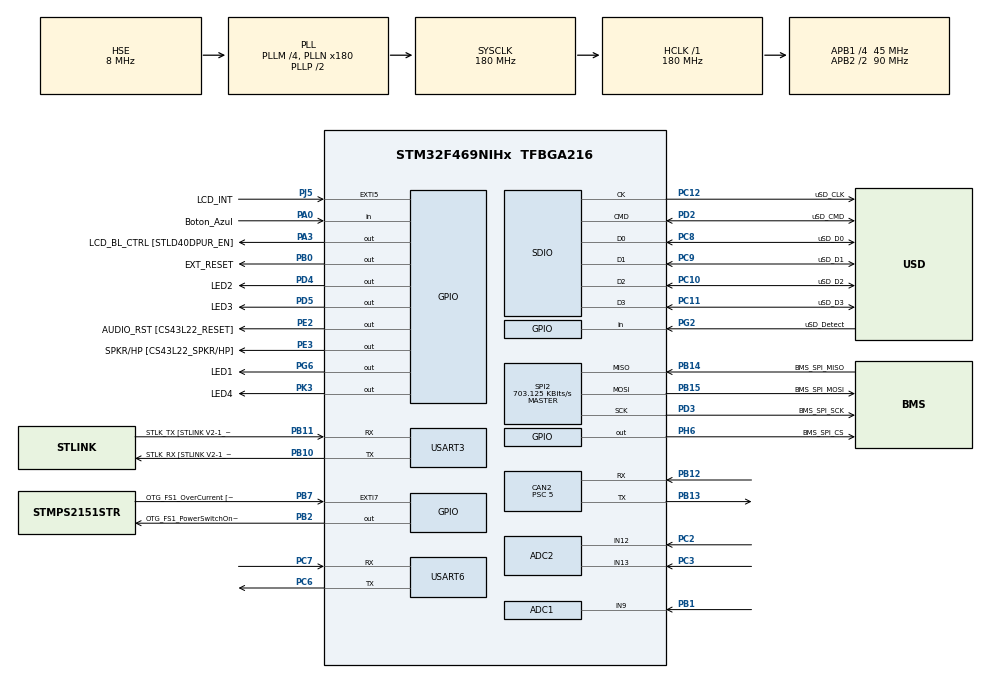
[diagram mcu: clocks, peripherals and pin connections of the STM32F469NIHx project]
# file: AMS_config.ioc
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ADC1.Channel-1\#ChannelRegularConversion=ADC_CHANNEL_9
ADC1.Channel-2\#ChannelRegularConversion=ADC_CHANNEL_TEMPSENSOR
ADC1.Channel-3\#ChannelRegularConversion=ADC_CHANNEL_VREFINT
ADC1.ClockPrescaler=ADC_CLOCK_SYNC_PCLK_DIV4
ADC1.DMAContinuousRequests=ENABLE
ADC1.ExternalTrigConv=ADC_EXTERNALTRIGCONV_T2_TRGO
ADC1.NbrOfConversion=3
ADC1.NbrOfConversionFlag=1
ADC1.Rank-1\#ChannelRegularConversion=1
ADC1.Rank-2\#ChannelRegularConversion=2
ADC1.Rank-3\#ChannelRegularConversion=3
ADC1.SamplingTime-1\#ChannelRegularConversion=ADC_SAMPLETIME_15CYCLES
ADC1.SamplingTime-2\#ChannelRegularConversion=ADC_SAMPLETIME_480CYCLES
ADC1.SamplingTime-3\#ChannelRegularConversion=ADC_SAMPLETIME_480CYCLES
ADC1.master=1
ADC2.Channel-0\#ChannelRegularConversion=ADC_CHANNEL_12
ADC2.Channel-1\#ChannelRegularConversion=ADC_CHANNEL_13
ADC2.ClockPrescaler=ADC_CLOCK_SYNC_PCLK_DIV4
ADC2.ContinuousConvMode=DISABLE
ADC2.DMAContinuousRequests=ENABLE
ADC2.ExternalTrigConv=ADC_EXTERNALTRIGCONV_T3_TRGO
ADC2.NbrOfConversion=2
ADC2.NbrOfConversionFlag=1
ADC2.Rank-0\#ChannelRegularConversion=1
ADC2.Rank-1\#ChannelRegularConversion=2
ADC2.SamplingTime-0\#ChannelRegularConversion=ADC_SAMPLETIME_15CYCLES
ADC2.SamplingTime-1\#ChannelRegularConversion=ADC_SAMPLETIME_15CYCLES
CAN2.BS1=CAN_BS1_15TQ
CAN2.BS2=CAN_BS2_2TQ
CAN2.CalculateBaudRate=500000
CAN2.CalculateTimeBit=2000
CAN2.CalculateTimeQuantum=111.11111111111111
CAN2.Prescaler=5
DSIHOST_CKN.GPIO_Label=DSI_CK_N
DSIHOST_CKN.Signal=DSIHOST_CKN
DSIHOST_CKP.GPIO_Label=DSI_CK_P
DSIHOST_CKP.Signal=DSIHOST_CKP
DSIHOST_D0N.GPIO_Label=DSI_D0_N
DSIHOST_D0N.Signal=DSIHOST_D0N
DSIHOST_D0P.GPIO_Label=DSI_D0_P
DSIHOST_D0P.Signal=DSIHOST_D0P
DSIHOST_D1N.GPIO_Label=DSI_D1_N
DSIHOST_D1N.Signal=DSIHOST_D1N
DSIHOST_D1P.GPIO_Label=DSI_D1_P
DSIHOST_D1P.Signal=DSIHOST_D1P
Dma.ADC1.1.Direction=DMA_PERIPH_TO_MEMORY
Dma.ADC1.1.FIFOMode=DMA_FIFOMODE_DISABLE
Dma.ADC1.1.Instance=DMA2_Stream0
Dma.ADC1.1.MemDataAlignment=DMA_MDATAALIGN_HALFWORD
Dma.ADC1.1.MemInc=DMA_MINC_ENABLE
Dma.ADC1.1.Mode=DMA_CIRCULAR
Dma.ADC1.1.PeriphDataAlignment=DMA_PDATAALIGN_HALFWORD
Dma.ADC1.1.PeriphInc=DMA_PINC_DISABLE
Dma.ADC1.1.Priority=DMA_PRIORITY_LOW
Dma.ADC2.0.Direction=DMA_PERIPH_TO_MEMORY
Dma.ADC2.0.FIFOMode=DMA_FIFOMODE_DISABLE
Dma.ADC2.0.Instance=DMA2_Stream2
Dma.ADC2.0.MemDataAlignment=DMA_MDATAALIGN_HALFWORD
Dma.ADC2.0.MemInc=DMA_MINC_ENABLE
Dma.ADC2.0.Mode=DMA_CIRCULAR
Dma.ADC2.0.PeriphDataAlignment=DMA_PDATAALIGN_HALFWORD
Dma.ADC2.0.PeriphInc=DMA_PINC_DISABLE
Dma.ADC2.0.Priority=DMA_PRIORITY_LOW
Dma.Request0=ADC2
Dma.Request1=ADC1
Dma.Request2=USART6_RX
Dma.USART6_RX.2.Direction=DMA_PERIPH_TO_MEMORY
Dma.USART6_RX.2.FIFOMode=DMA_FIFOMODE_DISABLE
Dma.USART6_RX.2.Instance=DMA2_Stream1
Dma.USART6_RX.2.MemDataAlignment=DMA_MDATAALIGN_BYTE
Dma.USART6_RX.2.MemInc=DMA_MINC_ENABLE
Dma.USART6_RX.2.Mode=DMA_CIRCULAR
Dma.USART6_RX.2.PeriphDataAlignment=DMA_PDATAALIGN_BYTE
Dma.USART6_RX.2.PeriphInc=DMA_PINC_DISABLE
Dma.USART6_RX.2.Priority=DMA_PRIORITY_LOW
FATFS.BSP.number=1
FATFS._USE_LFN=3
FATFS0.BSP.STBoard=false
FATFS0.BSP.api=Unknown
FATFS0.BSP.instance=PG2
FATFS0.BSP.ip=GPIO
FATFS0.BSP.mode=Input
FATFS0.BSP.name=Detect_SDIO
FATFS0.BSP.solution=PG2
FREERTOS.Tasks01=defaultTask,24,256,StartDefaultTask,Default,NULL,Dynamic,NULL,NULL;Task_ADC,24,256,ADC_Start,Default,NULL,Dynamic,NULL,NULL;Task_SD_Card,24,512,SD_Card_Start,Default,NULL,Dynamic,NULL,NULL;Task_CAN,24,256,CAN_Start,Default,NULL,Dynamic,NULL,NULL;Task_Flash_Memo,8,256,Flash_Memory_Start,Default,NULL,Dynamic,NULL,NULL;GPS_Task,24,256,GPS_Start_Task,Default,NULL,Dynamic,NULL,NULL
Mcu.Family=STM32F4
Mcu.Name=STM32F469NIHx
Mcu.Package=TFBGA216
NVIC.CAN2_RX0_IRQn=true\:5\:0\:false\:false\:true\:true\:true\:true\:true
NVIC.DMA2_Stream0_IRQn=true\:5\:0\:false\:false\:true\:true\:false\:true\:true
NVIC.DMA2_Stream1_IRQn=true\:5\:0\:false\:false\:true\:true\:false\:true\:true
NVIC.DMA2_Stream2_IRQn=true\:5\:0\:false\:false\:true\:true\:false\:true\:true
NVIC.PriorityGroup=NVIC_PRIORITYGROUP_4
NVIC.SDIO_IRQn=true\:5\:0\:false\:false\:true\:true\:true\:true\:true
NVIC.USART6_IRQn=true\:5\:0\:false\:false\:true\:true\:true\:true\:true
PA0/WKUP.GPIO_Label=Boton_Azul
PA0/WKUP.Signal=GPIO_Input
PA10.GPIO_Label=USB_FS1_ID
PA10.GPIO_Mode=GPIO_MODE_AF_PP
PA10.GPIO_PuPd=GPIO_NOPULL
PA10.GPIO_Speed=GPIO_SPEED_FREQ_VERY_HIGH
PA10.Signal=USB_OTG_FS_ID
PA11.GPIO_Label=USB_FS1_N
PA11.GPIO_Mode=GPIO_MODE_AF_PP
PA11.GPIO_PuPd=GPIO_NOPULL
PA11.GPIO_Speed=GPIO_SPEED_FREQ_VERY_HIGH
PA11.Signal=USB_OTG_FS_DM
PA12.GPIO_Label=USB_FS1_P
PA12.GPIO_Mode=GPIO_MODE_AF_PP
PA12.GPIO_PuPd=GPIO_NOPULL
PA12.GPIO_Speed=GPIO_SPEED_FREQ_VERY_HIGH
PA12.Signal=USB_OTG_FS_DP
PA13.GPIO_Label=SWDIO
PA13.Signal=SYS_JTMS-SWDIO
PA14.GPIO_Label=SWCLK
PA14.Signal=SYS_JTCK-SWCLK
PA3.GPIO_Label=LCD_BL_CTRL [STLD40DPUR_EN]
PA3.Signal=GPIO_Output
PA5.Signal=ADCx_IN5
PA9.GPIO_Label=VBUS_FS1
PA9.GPIO_Mode=GPIO_MODE_AF_PP
PA9.GPIO_PuPd=GPIO_NOPULL
PA9.GPIO_Speed=GPIO_SPEED_FREQ_VERY_HIGH
PA9.Signal=USB_OTG_FS_VBUS
PB0.GPIO_Label=EXT_RESET
PB0.Signal=GPIO_Output
PB1.Signal=ADCx_IN9
PB10.GPIO_Label=STLK_RX [STLINK V2-1_U2_RX]
PB10.Mode=Asynchronous
PB10.Signal=USART3_TX
PB11.GPIO_Label=STLK_TX [STLINK V2-1_U2_TX]
PB11.Mode=Asynchronous
PB11.Signal=USART3_RX
PB12.Mode=CAN_Activate
PB12.Signal=CAN2_RX
PB13.Mode=CAN_Activate
PB13.Signal=CAN2_TX
PB14.GPIO_Label=BMS_SPI_MISO
PB14.Mode=Full_Duplex_Master
PB14.Signal=SPI2_MISO
PB15.GPIO_Label=BMS_SPI_MOSI
PB15.Mode=Full_Duplex_Master
PB15.Signal=SPI2_MOSI
PB2/BOOT1.GPIO_Label=OTG_FS1_PowerSwitchOn [STMPS2151STR_En]
PB2/BOOT1.Signal=GPIO_Output
PB3.GPIO_Label=I2S3_CK
PB3.GPIO_Mode=GPIO_MODE_AF_PP
PB3.GPIO_PuPd=GPIO_NOPULL
PB3.GPIO_Speed=GPIO_SPEED_FREQ_LOW
PB3.Signal=I2S3_CK
PB6.GPIO_Label=QSPI_BK1_NCS [N25Q128A13EF840F_S]
PB6.GPIO_Mode=GPIO_MODE_AF_PP
PB6.GPIO_PuPd=GPIO_NOPULL
PB6.GPIO_Speed=GPIO_SPEED_FREQ_VERY_HIGH
PB6.Signal=QUADSPI_BK1_NCS
PB7.GPIO_Label=OTG_FS1_OverCurrent [STMPS2151STR_FAULT]
PB7.GPIO_ModeDefaultEXTI=GPIO_MODE_IT_RISING
PB7.GPIO_PuPd=GPIO_NOPULL
PB7.Signal=GPXTI7
PB8.GPIO_Label=I2C1_SCL
PB8.GPIO_Mode=GPIO_MODE_AF_OD
PB8.GPIO_PuPdOD=GPIO_PULLUP
PB8.GPIO_Speed=GPIO_SPEED_FREQ_VERY_HIGH
PB8.Signal=I2C1_SCL
PB9.GPIO_Label=I2C1_SDA
PB9.GPIO_Mode=GPIO_MODE_AF_OD
PB9.GPIO_PuPdOD=GPIO_PULLUP
PB9.GPIO_Speed=GPIO_SPEED_FREQ_VERY_HIGH
PB9.Signal=I2C1_SDA
PC0.GPIO_Label=SDNWE [MT48LC4M32B2B5-6A_WE]
PC0.Signal=FMC_SDNWE
PC10.GPIO_Label=uSD_D2
PC10.GPIO_Mode=GPIO_MODE_AF_PP
PC10.GPIO_PuPd=GPIO_NOPULL
PC10.GPIO_Speed_High_Default=GPIO_SPEED_FREQ_VERY_HIGH
PC10.Mode=SD_4_bits_Wide_bus
PC10.Signal=SDIO_D2
PC11.GPIO_Label=uSD_D3
PC11.GPIO_Mode=GPIO_MODE_AF_PP
PC11.GPIO_PuPd=GPIO_NOPULL
PC11.GPIO_Speed_High_Default=GPIO_SPEED_FREQ_VERY_HIGH
PC11.Mode=SD_4_bits_Wide_bus
PC11.Signal=SDIO_D3
PC12.GPIO_Label=uSD_CLK
PC12.GPIO_Mode=GPIO_MODE_AF_PP
PC12.GPIO_PuPd=GPIO_NOPULL
PC12.GPIO_Speed_High_Default=GPIO_SPEED_FREQ_VERY_HIGH
PC12.Mode=SD_4_bits_Wide_bus
PC12.Signal=SDIO_CK
PC14/OSC32_IN.Mode=LSE-External-Oscillator
PC14/OSC32_IN.Signal=RCC_OSC32_IN
PC15/OSC32_OUT.Mode=LSE-External-Oscillator
PC15/OSC32_OUT.Signal=RCC_OSC32_OUT
PC2.Signal=ADCx_IN12
PC3.Signal=ADCx_IN13
PC6.Mode=Asynchronous
PC6.Signal=USART6_TX
PC7.Mode=Asynchronous
PC7.Signal=USART6_RX
PC8.GPIO_Label=uSD_D0
PC8.GPIO_Mode=GPIO_MODE_AF_PP
PC8.GPIO_PuPd=GPIO_NOPULL
PC8.GPIO_Speed_High_Default=GPIO_SPEED_FREQ_VERY_HIGH
PC8.Mode=SD_4_bits_Wide_bus
PC8.Signal=SDIO_D0
PC9.GPIO_Label=uSD_D1
PC9.GPIO_Mode=GPIO_MODE_AF_PP
PC9.GPIO_PuPd=GPIO_NOPULL
PC9.GPIO_Speed_High_Default=GPIO_SPEED_FREQ_VERY_HIGH
PC9.Mode=SD_4_bits_Wide_bus
PC9.Signal=SDIO_D1
PD0.GPIO_Label=D2
PD0.GPIO_Mode=GPIO_MODE_AF_PP
PD0.GPIO_PuPd=GPIO_NOPULL
PD0.GPIO_Speed_High_Default=GPIO_SPEED_FREQ_VERY_HIGH
PD0.Signal=FMC_D2_DA2
PD1.GPIO_Label=D3
PD1.GPIO_Mode=GPIO_MODE_AF_PP
PD1.GPIO_PuPd=GPIO_NOPULL
PD1.GPIO_Speed_High_Default=GPIO_SPEED_FREQ_VERY_HIGH
PD1.Signal=FMC_D3_DA3
PD3.GPIO_Label=BMS_SPI_SCK
PD3.Mode=Full_Duplex_Master
PD3.Signal=SPI2_SCK
PD10.GPIO_Label=D15
PD10.Signal=FMC_D15_DA15
PD13.GPIO_Label=MIC_CK [MP34DT01TR_CLK]
PD13.Signal=S_TIM4_CH2
PD14.GPIO_Label=D0
PD14.Signal=FMC_D0_DA0
PD15.GPIO_Label=D1
PD15.Signal=FMC_D1_DA1
PD2.GPIO_Label=uSD_CMD
PD2.GPIO_Mode=GPIO_MODE_AF_PP
PD2.GPIO_PuPd=GPIO_NOPULL
PD2.GPIO_Speed_High_Default=GPIO_SPEED_FREQ_VERY_HIGH
PD2.Mode=SD_4_bits_Wide_bus
PD2.Signal=SDIO_CMD
PD4.GPIO_Label=LED2
PD4.GPIO_ModeDefaultOutputPP=GPIO_MODE_OUTPUT_PP
PD4.GPIO_PuPd=GPIO_NOPULL
PD4.GPIO_Speed=GPIO_SPEED_FREQ_LOW
PD4.Signal=GPIO_Output
PD5.GPIO_Label=LED3
PD5.GPIO_ModeDefaultOutputPP=GPIO_MODE_OUTPUT_PP
PD5.GPIO_PuPd=GPIO_NOPULL
PD5.GPIO_Speed=GPIO_SPEED_FREQ_LOW
PD5.Signal=GPIO_Output
PD6.GPIO_Label=MIC_DATA [MP34DT01TR_DOUT]
PD6.GPIO_Mode=GPIO_MODE_AF_PP
PD6.GPIO_PuPd=GPIO_NOPULL
PD6.GPIO_Speed=GPIO_SPEED_FREQ_LOW
PD6.Signal=SAI1_SD_A
PD8.GPIO_Label=D13
PD8.Signal=FMC_D13_DA13
PD9.GPIO_Label=D14
PD9.Signal=FMC_D14_DA14
PE0.GPIO_Label=FMC_NBL0 [ MT48LC4M32B2B5-6A_DQM0]
PE0.GPIO_Mode=GPIO_MODE_AF_PP
PE0.GPIO_PuPd=GPIO_NOPULL
PE0.GPIO_Speed_High_Default=GPIO_SPEED_FREQ_VERY_HIGH
PE0.Signal=FMC_NBL0
PE1.GPIO_Label=FMC_NBL1 [ MT48LC4M32B2B5-6A_DQM1]
PE1.GPIO_Mode=GPIO_MODE_AF_PP
PE1.GPIO_PuPd=GPIO_NOPULL
PE1.GPIO_Speed_High_Default=GPIO_SPEED_FREQ_VERY_HIGH
PE1.Signal=FMC_NBL1
PE10.GPIO_Label=D7
PE10.Signal=FMC_D7_DA7
PE11.GPIO_Label=D8
PE11.Signal=FMC_D8_DA8
PE12.GPIO_Label=D9
PE12.Signal=FMC_D9_DA9
PE13.GPIO_Label=D10
PE13.Signal=FMC_D10_DA10
PE14.GPIO_Label=D11
PE14.Signal=FMC_D11_DA11
PE15.GPIO_Label=D12
PE15.Signal=FMC_D12_DA12
PE2.GPIO_Label=AUDIO_RST [CS43L22_RESET]
PE2.GPIO_ModeDefaultOutputPP=GPIO_MODE_OUTPUT_PP
PE2.GPIO_PuPd=GPIO_NOPULL
PE2.GPIO_Speed=GPIO_SPEED_FREQ_LOW
PE2.Signal=GPIO_Output
PE3.GPIO_Label=SPKR/HP [CS43L22_SPKR/HP]
PE3.GPIO_ModeDefaultOutputPP=GPIO_MODE_OUTPUT_PP
PE3.GPIO_PuPd=GPIO_NOPULL
PE3.GPIO_Speed=GPIO_SPEED_FREQ_LOW
PE3.Signal=GPIO_Output
PE4.GPIO_Label=SAI1_FSA [CS43L22_LRCK]
PE4.GPIO_Mode=GPIO_MODE_AF_PP
PE4.GPIO_PuPd=GPIO_NOPULL
PE4.GPIO_Speed=GPIO_SPEED_FREQ_LOW
PE4.Signal=SAI1_FS_A
PE5.GPIO_Label=SAI1_SCKA [CS43L22_CLK]
PE5.GPIO_Mode=GPIO_MODE_AF_PP
PE5.GPIO_PuPd=GPIO_NOPULL
PE5.GPIO_Speed=GPIO_SPEED_FREQ_LOW
PE5.Signal=SAI1_SCK_A
PE7.GPIO_Label=D4
PE7.Signal=FMC_D4_DA4
PE8.GPIO_Label=D5
PE8.Signal=FMC_D5_DA5
PE9.GPIO_Label=D6
PE9.Signal=FMC_D6_DA6
PF0.GPIO_Label=A0
PF0.GPIO_Mode=GPIO_MODE_AF_PP
PF0.GPIO_PuPd=GPIO_NOPULL
PF0.GPIO_Speed_High_Default=GPIO_SPEED_FREQ_VERY_HIGH
PF0.Signal=FMC_A0
PF1.GPIO_Label=A1
PF1.GPIO_Mode=GPIO_MODE_AF_PP
PF1.GPIO_PuPd=GPIO_NOPULL
PF1.GPIO_Speed_High_Default=GPIO_SPEED_FREQ_VERY_HIGH
PF1.Signal=FMC_A1
PF10.GPIO_Label=QSPI_CLK [N25Q128A13EF840F_C]
PF10.Signal=QUADSPI_CLK
PF11.GPIO_Label=SDNMT48LC4M32B2B5-6A_RAS]RAS [
PF11.Signal=FMC_SDNRAS
PF12.GPIO_Label=A6
PF12.Signal=FMC_A6
PF13.GPIO_Label=A7
PF13.Signal=FMC_A7
PF14.GPIO_Label=A8
PF14.Signal=FMC_A8
PF15.GPIO_Label=A9
PF15.Signal=FMC_A9
PF2.GPIO_Label=A2
PF2.GPIO_Mode=GPIO_MODE_AF_PP
PF2.GPIO_PuPd=GPIO_NOPULL
PF2.GPIO_Speed_High_Default=GPIO_SPEED_FREQ_VERY_HIGH
PF2.Signal=FMC_A2
PF3.GPIO_Label=A3
PF3.GPIO_Mode=GPIO_MODE_AF_PP
PF3.GPIO_PuPd=GPIO_NOPULL
PF3.GPIO_Speed_High_Default=GPIO_SPEED_FREQ_VERY_HIGH
PF3.Signal=FMC_A3
PF4.GPIO_Label=A4
PF4.GPIO_Mode=GPIO_MODE_AF_PP
PF4.GPIO_PuPd=GPIO_NOPULL
PF4.GPIO_Speed_High_Default=GPIO_SPEED_FREQ_VERY_HIGH
PF4.Signal=FMC_A4
PF5.GPIO_Label=A5
PF5.Signal=FMC_A5
PF6.GPIO_Label=QSPI_BK1_IO3 [N25Q128A13EF840F_DQ3]
PF6.Signal=QUADSPI_BK1_IO3
PF7.GPIO_Label=QSPI_BK1_IO2 [N25Q128A13EF840F_DQ2]
PF7.Signal=QUADSPI_BK1_IO2
PF8.GPIO_Label=QSPI_BK1_IO0 [N25Q128A13EF840F_DQ0]
PF8.Signal=QUADSPI_BK1_IO0
PF9.GPIO_Label=QSPI_BK1_IO1 [N25Q128A13EF840F_DQ1]
PF9.Signal=QUADSPI_BK1_IO1
PG0.GPIO_Label=A10
PG0.Signal=FMC_A10
PG1.GPIO_Label=A11
PG1.Signal=FMC_A11
PG15.GPIO_Label=SDNCAS [MT48LC4M32B2B5-6A_CAS]
PG15.GPIO_Mode=GPIO_MODE_AF_PP
PG15.GPIO_PuPd=GPIO_NOPULL
PG15.GPIO_Speed_High_Default=GPIO_SPEED_FREQ_VERY_HIGH
PG15.Signal=FMC_SDNCAS
PG2.GPIO_Label=uSD_Detect
PG2.Signal=GPIO_Input
PG4.Signal=FMC_A14_BA0
PG5.Signal=FMC_A15_BA1
PG6.GPIO_Label=LED1
PG6.GPIO_ModeDefaultOutputPP=GPIO_MODE_OUTPUT_PP
PG6.GPIO_PuPd=GPIO_NOPULL
PG6.GPIO_Speed=GPIO_SPEED_FREQ_LOW
PG6.Signal=GPIO_Output
PG7.GPIO_Label=SAI1_MCLKA [CS43L22_MCLK]
PG7.GPIO_Mode=GPIO_MODE_AF_PP
PG7.GPIO_PuPd=GPIO_NOPULL
PG7.GPIO_Speed=GPIO_SPEED_FREQ_LOW
PG7.Signal=SAI1_MCLK_A
PG8.GPIO_Label=SDCLK [MT48LC4M32B2B5-6A_CLK]
PG8.GPIO_Mode=GPIO_MODE_AF_PP
PG8.GPIO_PuPd=GPIO_NOPULL
PG8.GPIO_Speed_High_Default=GPIO_SPEED_FREQ_VERY_HIGH
PG8.Signal=FMC_SDCLK
PH0/OSC_IN.Mode=HSE-External-Oscillator
PH0/OSC_IN.Signal=RCC_OSC_IN
PH1/OSC_OUT.Mode=HSE-External-Oscillator
PH1/OSC_OUT.Signal=RCC_OSC_OUT
PH10.GPIO_Label=D18
PH10.Signal=FMC_D18
PH11.GPIO_Label=D19
PH11.Signal=FMC_D19
PH12.GPIO_Label=D20
PH12.Signal=FMC_D20
PH13.GPIO_Label=D21
PH13.GPIO_Mode=GPIO_MODE_AF_PP
PH13.GPIO_PuPd=GPIO_NOPULL
PH13.GPIO_Speed_High_Default=GPIO_SPEED_FREQ_VERY_HIGH
PH13.Signal=FMC_D21
PH14.GPIO_Label=D22
PH14.GPIO_Mode=GPIO_MODE_AF_PP
PH14.GPIO_PuPd=GPIO_NOPULL
PH14.GPIO_Speed_High_Default=GPIO_SPEED_FREQ_VERY_HIGH
PH14.Signal=FMC_D22
PH15.GPIO_Label=D23
PH15.GPIO_Mode=GPIO_MODE_AF_PP
PH15.GPIO_PuPd=GPIO_NOPULL
PH15.GPIO_Speed_High_Default=GPIO_SPEED_FREQ_VERY_HIGH
PH15.Signal=FMC_D23
PH2.GPIO_Label=SDCKE0 [MT48LC4M32B2B5-6A_CKE]
PH2.Signal=FMC_SDCKE0
PH3.GPIO_Label=SDNE0 [MT48LC4M32B2B5-6A_CS]
PH3.GPIO_Mode=GPIO_MODE_AF_PP
PH3.GPIO_PuPd=GPIO_NOPULL
PH3.GPIO_Speed_High_Default=GPIO_SPEED_FREQ_VERY_HIGH
PH3.Signal=FMC_SDNE0
PH4.GPIO_Label=I2C2_SCL [CS43L22_SCL]
PH4.GPIO_Mode=GPIO_MODE_AF_OD
PH4.GPIO_PuPdOD=GPIO_PULLUP
PH4.GPIO_Speed=GPIO_SPEED_FREQ_VERY_HIGH
PH4.Signal=I2C2_SCL
PH5.GPIO_Label=I2C2_SDA [CS43L22_SDA]
PH5.GPIO_Mode=GPIO_MODE_AF_OD
PH5.GPIO_PuPdOD=GPIO_PULLUP
PH5.GPIO_Speed=GPIO_SPEED_FREQ_VERY_HIGH
PH5.Signal=I2C2_SDA
PH6.GPIO_Label=BMS_SPI_CS
PH6.GPIO_PuPd=GPIO_NOPULL
PH6.PinState=GPIO_PIN_SET
PH6.Signal=GPIO_Output
PH8.GPIO_Label=D16
PH8.Signal=FMC_D16
PH9.GPIO_Label=D17
PH9.Signal=FMC_D17
PI0.GPIO_Label=D24
PI0.GPIO_Mode=GPIO_MODE_AF_PP
PI0.GPIO_PuPd=GPIO_NOPULL
PI0.GPIO_Speed_High_Default=GPIO_SPEED_FREQ_VERY_HIGH
PI0.Signal=FMC_D24
PI1.GPIO_Label=D25
PI1.GPIO_Mode=GPIO_MODE_AF_PP
PI1.GPIO_PuPd=GPIO_NOPULL
PI1.GPIO_Speed_High_Default=GPIO_SPEED_FREQ_VERY_HIGH
PI1.Signal=FMC_D25
PI10.GPIO_Label=D31
PI10.GPIO_Mode=GPIO_MODE_AF_PP
PI10.GPIO_PuPd=GPIO_NOPULL
PI10.GPIO_Speed_High_Default=GPIO_SPEED_FREQ_VERY_HIGH
PI10.Signal=FMC_D31
PI2.GPIO_Label=D26
PI2.GPIO_Mode=GPIO_MODE_AF_PP
PI2.GPIO_PuPd=GPIO_NOPULL
PI2.GPIO_Speed_High_Default=GPIO_SPEED_FREQ_VERY_HIGH
PI2.Signal=FMC_D26
PI3.GPIO_Label=D27
PI3.GPIO_Mode=GPIO_MODE_AF_PP
PI3.GPIO_PuPd=GPIO_NOPULL
PI3.GPIO_Speed_High_Default=GPIO_SPEED_FREQ_VERY_HIGH
PI3.Signal=FMC_D27
PI4.GPIO_Label=FMC_NBL2 [MT48LC4M32B2B5-6A_DQM2]
PI4.GPIO_Mode=GPIO_MODE_AF_PP
PI4.GPIO_PuPd=GPIO_NOPULL
PI4.GPIO_Speed_High_Default=GPIO_SPEED_FREQ_VERY_HIGH
PI4.Signal=FMC_NBL2
PI5.GPIO_Label=FMC_NBL3 [MT48LC4M32B2B5-6A_DQM3]
PI5.GPIO_Mode=GPIO_MODE_AF_PP
PI5.GPIO_PuPd=GPIO_NOPULL
PI5.GPIO_Speed_High_Default=GPIO_SPEED_FREQ_VERY_HIGH
PI5.Signal=FMC_NBL3
PI6.GPIO_Label=D28
PI6.GPIO_Mode=GPIO_MODE_AF_PP
PI6.GPIO_PuPd=GPIO_NOPULL
PI6.GPIO_Speed_High_Default=GPIO_SPEED_FREQ_VERY_HIGH
PI6.Signal=FMC_D28
PI7.GPIO_Label=D29
PI7.GPIO_Mode=GPIO_MODE_AF_PP
PI7.GPIO_PuPd=GPIO_NOPULL
PI7.GPIO_Speed_High_Default=GPIO_SPEED_FREQ_VERY_HIGH
PI7.Signal=FMC_D29
PI9.GPIO_Label=D30
PI9.GPIO_Mode=GPIO_MODE_AF_PP
PI9.GPIO_PuPd=GPIO_NOPULL
PI9.GPIO_Speed_High_Default=GPIO_SPEED_FREQ_VERY_HIGH
PI9.Signal=FMC_D30
PJ2.GPIO_Label=DSI_TE
PJ2.Signal=DSIHOST_TE
PJ5.GPIO_Label=LCD_INT
PJ5.Signal=GPXTI5
PK3.GPIO_Label=LED4
PK3.GPIO_ModeDefaultOutputPP=GPIO_MODE_OUTPUT_PP
PK3.GPIO_PuPd=GPIO_NOPULL
PK3.GPIO_Speed=GPIO_SPEED_FREQ_LOW
PK3.Signal=GPIO_Output
ProjectManager.HeapSize=0x400
ProjectManager.StackSize=0x400
ProjectManager.TargetToolchain=STM32CubeIDE
RCC.AHBFreq_Value=180000000
RCC.APB1CLKDivider=RCC_HCLK_DIV4
RCC.APB1Freq_Value=45000000
RCC.APB1TimFreq_Value=90000000
RCC.APB2CLKDivider=RCC_HCLK_DIV2
RCC.APB2Freq_Value=90000000
RCC.APB2TimFreq_Value=180000000
RCC.CortexFreq_Value=180000000
RCC.HCLKFreq_Value=180000000
RCC.HSE_VALUE=8000000
RCC.PLLM=4
RCC.PLLN=180
RCC.PLLQ=8
RCC.PLLSourceVirtual=RCC_PLLSOURCE_HSE
RCC.SYSCLKFreq_VALUE=180000000
RCC.SYSCLKSource=RCC_SYSCLKSOURCE_PLLCLK
RCC.USBFreq_Value=45000000
RCC.VCOOutputFreq_Value=360000000
SDIO.ClockDiv=4
SH.ADCx_IN12.0=ADC2_IN12,IN12
SH.ADCx_IN13.0=ADC2_IN13,IN13
SH.ADCx_IN5.0=ADC2_IN5
SH.ADCx_IN9.0=ADC2_IN9
SH.ADCx_IN9.1=ADC1_IN9,IN9
SH.FMC_A0.0=FMC_A0
SH.FMC_A1.0=FMC_A1
SH.FMC_A10.0=FMC_A10
SH.FMC_A11.0=FMC_A11
SH.FMC_A14_BA0.0=FMC_BA0
SH.FMC_A15_BA1.0=FMC_BA1
SH.FMC_A2.0=FMC_A2
SH.FMC_A3.0=FMC_A3
SH.FMC_A4.0=FMC_A4
SH.FMC_A5.0=FMC_A5
SH.FMC_A6.0=FMC_A6
SH.FMC_A7.0=FMC_A7
SH.FMC_A8.0=FMC_A8
SH.FMC_A9.0=FMC_A9
SH.FMC_D0_DA0.0=FMC_D0
SH.FMC_D10_DA10.0=FMC_D10
SH.FMC_D11_DA11.0=FMC_D11
SH.FMC_D12_DA12.0=FMC_D12
SH.FMC_D13_DA13.0=FMC_D13
SH.FMC_D14_DA14.0=FMC_D14
SH.FMC_D15_DA15.0=FMC_D15
SH.FMC_D16.0=FMC_D16
SH.FMC_D17.0=FMC_D17
SH.FMC_D18.0=FMC_D18
SH.FMC_D19.0=FMC_D19
SH.FMC_D1_DA1.0=FMC_D1
SH.FMC_D20.0=FMC_D20
SH.FMC_D21.0=FMC_D21
SH.FMC_D22.0=FMC_D22
SH.FMC_D23.0=FMC_D23
SH.FMC_D24.0=FMC_D24
SH.FMC_D25.0=FMC_D25
SH.FMC_D26.0=FMC_D26
SH.FMC_D27.0=FMC_D27
SH.FMC_D28.0=FMC_D28
SH.FMC_D29.0=FMC_D29
SH.FMC_D2_DA2.0=FMC_D2
SH.FMC_D30.0=FMC_D30
SH.FMC_D31.0=FMC_D31
SH.FMC_D3_DA3.0=FMC_D3
SH.FMC_D4_DA4.0=FMC_D4
SH.FMC_D5_DA5.0=FMC_D5
SH.FMC_D6_DA6.0=FMC_D6
SH.FMC_D7_DA7.0=FMC_D7
SH.FMC_D8_DA8.0=FMC_D8
SH.FMC_D9_DA9.0=FMC_D9
SH.FMC_NBL0.0=FMC_NBL0
SH.FMC_NBL1.0=FMC_NBL1
SH.FMC_NBL2.0=FMC_NBL2
SH.FMC_NBL3.0=FMC_NBL3
SH.FMC_SDCLK.0=FMC_SDCLK
SH.FMC_SDNCAS.0=FMC_SDNCAS
SH.FMC_SDNRAS.0=FMC_SDNRAS
SH.FMC_SDNWE.0=FMC_SDNWE
SH.S_TIM4_CH2.0=TIM4_CH2
TIM2.Period=25000-1
TIM2.Prescaler=90-1
TIM2.TIM_MasterOutputTrigger=TIM_TRGO_UPDATE
TIM3.Period=200-1
TIM3.Prescaler=90-1
TIM3.TIM_MasterOutputTrigger=TIM_TRGO_UPDATE
USART3.VirtualMode=VM_ASYNC
USART6.VirtualMode=VM_ASYNC
SPI2.BaudRatePrescaler=SPI_BAUDRATEPRESCALER_64
SPI2.CLKPhase=SPI_PHASE_2EDGE
SPI2.CLKPolarity=SPI_POLARITY_HIGH
SPI2.CalculateBaudRate=703.125 KBits/s
SPI2.Direction=SPI_DIRECTION_2LINES
SPI2.Mode=SPI_MODE_MASTER
SPI2.VirtualType=VM_MASTER
VP_ADC1_TempSens_Input.Mode=IN-TempSens
VP_ADC1_Vref_Input.Mode=IN-Vrefint
VP_FATFS_VS_SDIO.Mode=SDIO
VP_FREERTOS_VS_CMSIS_V2.Mode=CMSIS_V2
VP_TIM2_VS_ClockSourceINT.Mode=Internal
VP_TIM3_VS_ClockSourceINT.Mode=Internal
board=STM32F469I-DISCO

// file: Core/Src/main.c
/* USER CODE BEGIN Header */
/**
 ******************************************************************************
 * @file           : main.c
 * @brief          : Main program body
 ******************************************************************************
 * @attention
 *
 * Copyright (c) 2026 STMicroelectronics.
 * All rights reserved.
 *
 * This software is licensed under terms that can be found in the LICENSE file
 * in the root directory of this software component.
 * If no LICENSE file comes with this software, it is provided AS-IS.
 *
 ******************************************************************************
 */
/* USER CODE END Header */
#include "main.h"
#include "cmsis_os.h"
#include "fatfs.h"

/* USER CODE BEGIN Includes */
#include "stdio.h"
#include "AMS_task_config.h"                   /* Compile-time task/feature flags */
#include "Middleware/AMS_Logger_Task.h"
#include "Middleware/AMS_Led_Task.h"
#include "Middleware/AMS_DataBroker.h"
#include "Middleware/AMS_ADC_Task.h"
#include "Middleware/AMS_CAN_Task.h"
#include "Middleware/AMS_Flash_Task.h"
#include "Middleware/AMS_GPS_Task.h"
#include "Middleware/AMS_Algorithms_Task.h"
#include "Middleware/AMS_BMS_Task.h"
/* USER CODE END Includes */

ADC_HandleTypeDef hadc1;
ADC_HandleTypeDef hadc2;
DMA_HandleTypeDef hdma_adc1;
DMA_HandleTypeDef hdma_adc2;

CAN_HandleTypeDef hcan2;

SPI_HandleTypeDef hspi2;

SD_HandleTypeDef hsd;

TIM_HandleTypeDef htim2;
TIM_HandleTypeDef htim3;

UART_HandleTypeDef huart3;
UART_HandleTypeDef huart6;
DMA_HandleTypeDef hdma_usart6_rx;

DMA_HandleTypeDef hdma_sdio_rx;
DMA_HandleTypeDef hdma_sdio_tx;

/* Definitions for defaultTask */
osThreadId_t defaultTaskHandle;
const osThreadAttr_t defaultTask_attributes = {
  .name = "defaultTask",
  .stack_size = 256 * 4,
  .priority = (osPriority_t) osPriorityNormal,
};
/* Definitions for Task_ADC */
osThreadId_t Task_ADCHandle;
const osThreadAttr_t Task_ADC_attributes = {
  .name = "Task_ADC",
  .stack_size = 256 * 4,
  .priority = (osPriority_t) osPriorityNormal,
};
/* Definitions for Task_SD_Card */
osThreadId_t Task_SD_CardHandle;
const osThreadAttr_t Task_SD_Card_attributes = {
  .name = "Task_SD_Card",
  .stack_size = 512 * 4,
  .priority = (osPriority_t) osPriorityNormal,
};
/* Definitions for Task_CAN */
osThreadId_t Task_CANHandle;
const osThreadAttr_t Task_CAN_attributes = {
  .name = "Task_CAN",
  .stack_size = 256 * 4,
  .priority = (osPriority_t) osPriorityNormal,
};
/* Definitions for Task_Flash_Memo */
osThreadId_t Task_Flash_MemoHandle;
const osThreadAttr_t Task_Flash_Memo_attributes = {
  .name = "Task_Flash_Memo",
  .stack_size = 256 * 4,
  .priority = (osPriority_t) osPriorityLow,
};
/* Definitions for GPS_Task */
osThreadId_t GPS_TaskHandle;
const osThreadAttr_t GPS_Task_attributes = {
  .name = "GPS_Task",
  .stack_size = 256 * 4,
  .priority = (osPriority_t) osPriorityNormal,
};
/* Definitions for Task_BMS */
osThreadId_t Task_BMSHandle;
const osThreadAttr_t Task_BMS_attributes = {
  .name = "Task_BMS",
  .stack_size = 256 * 4,
  .priority = (osPriority_t) osPriorityNormal,
};

void SystemClock_Config(void);
static void MX_GPIO_Init(void);
static void MX_DMA_Init(void);
static void MX_USART3_UART_Init(void);
static void MX_ADC1_Init(void);
static void MX_ADC2_Init(void);
static void MX_TIM3_Init(void);
static void MX_TIM2_Init(void);
static void MX_SDIO_SD_Init(void);
static void MX_CAN2_Init(void);
static void MX_USART6_UART_Init(void);
static void MX_SPI2_Init(void);
void StartDefaultTask(void *argument);
void ADC_Start(void *argument);
void SD_Card_Start(void *argument);
void CAN_Start(void *argument);
void Flash_Memory_Start(void *argument);
void GPS_Start_Task(void *argument);
void BMS_Start(void *argument);

int main(void)
{

  /* MCU Configuration--------------------------------------------------------*/

  /* Reset of all peripherals, Initializes the Flash interface and the Systick. */
  HAL_Init();

  /* Configure the system clock */
  SystemClock_Config();

  /* Initialize all configured peripherals */
  MX_GPIO_Init();
  MX_DMA_Init();
  MX_USART3_UART_Init();
  MX_ADC1_Init();
  MX_ADC2_Init();
  MX_TIM3_Init();
  MX_TIM2_Init();
  MX_SDIO_SD_Init();
  MX_FATFS_Init();
  MX_CAN2_Init();
  MX_USART6_UART_Init();
  MX_SPI2_Init();
  /* USER CODE BEGIN 2 */

	/* --- Shared infrastructure init (must run before any task) --- */
	b_Broker_Init();
	vd_LED_Manager_Init();  /* Drives all 4 LEDs to a known OFF state; without
	                          * this they stay ON from boot (active-low + CubeMX
	                          * leaves the pins RESET). Must run before any task
	                          * calls vd_LED_Manager_SetMode(). */

  /* USER CODE END 2 */

  /* Init scheduler */
  osKernelInitialize();

  /* Create the thread(s) */
  /* creation of defaultTask (always on — dashboard/general housekeeping) */
  defaultTaskHandle = osThreadNew(StartDefaultTask, NULL, &defaultTask_attributes);

  /* Threads below are gated by AMS_task_config.h so a disabled task doesn't
   * even get a TCB/stack allocated — previously all six were always created
   * and each disabled one exited immediately on first run via its own
   * #if TASK_*_ENABLE / osThreadExit() (still in place, harmless belt-and-
   * braces), which cost RAM and made `main.c` look like six tasks run when
   * some don't. */
#if (TASK_ADC_ENABLE == 1)
  /* creation of Task_ADC */
  Task_ADCHandle = osThreadNew(ADC_Start, NULL, &Task_ADC_attributes);
#endif

#if (TASK_SD_CARD_ENABLE == 1) || (FEATURE_LOGGER_PRINT_ENABLE == 1)
  /* creation of Task_SD_Card — this thread also hosts the terminal dashboard
   * printer (FEATURE_LOGGER_PRINT_ENABLE), which is independent of SD-card
   * logging (TASK_SD_CARD_ENABLE). Must match the #if inside SD_Card_Start()
   * below, or the dashboard silently stops working whenever SD logging is
   * disabled. */
  Task_SD_CardHandle = osThreadNew(SD_Card_Start, NULL, &Task_SD_Card_attributes);
#endif

#if (TASK_CAN_ENABLE == 1)
  /* creation of Task_CAN */
  Task_CANHandle = osThreadNew(CAN_Start, NULL, &Task_CAN_attributes);
#endif

#if (TASK_FLASH_MEMO_ENABLE == 1)
  /* creation of Task_Flash_Memo */
  Task_Flash_MemoHandle = osThreadNew(Flash_Memory_Start, NULL, &Task_Flash_Memo_attributes);
#endif

#if (TASK_GPS_ENABLE == 1)
  /* creation of GPS_Task */
  GPS_TaskHandle = osThreadNew(GPS_Start_Task, NULL, &GPS_Task_attributes);
#endif

#if (TASK_BMS_ENABLE == 1)
  /* creation of Task_BMS */
  Task_BMSHandle = osThreadNew(BMS_Start, NULL, &Task_BMS_attributes);
#endif

  /* USER CODE BEGIN RTOS_THREADS */
#if TASK_FLASH_MEMO_ENABLE
  /* Must run before osKernelStart(): other tasks read AMS_Persistent_Config_t
   * from the Broker as soon as they start, with no guarantee the Flash task
   * has run first (all tasks share the same priority). Flash HAL reads don't
   * need the scheduler running, so load it here instead. */
  vd_Flash_Task_Init();
#endif
  /* USER CODE END RTOS_THREADS */

  /* Start scheduler */
  osKernelStart();

  /* We should never get here as control is now taken by the scheduler */

  /* Infinite loop */
  while (1) {

  }
}

void SystemClock_Config(void)
{
  RCC_OscInitTypeDef RCC_OscInitStruct = {0};
  RCC_ClkInitTypeDef RCC_ClkInitStruct = {0};

  /** Configure the main internal regulator output voltage
  */
  __HAL_RCC_PWR_CLK_ENABLE();
  __HAL_PWR_VOLTAGESCALING_CONFIG(PWR_REGULATOR_VOLTAGE_SCALE1);

  /** Initializes the RCC Oscillators according to the specified parameters
  * in the RCC_OscInitTypeDef structure.
  */
  RCC_OscInitStruct.OscillatorType = RCC_OSCILLATORTYPE_HSE;
  RCC_OscInitStruct.HSEState = RCC_HSE_ON;
  RCC_OscInitStruct.PLL.PLLState = RCC_PLL_ON;
  RCC_OscInitStruct.PLL.PLLSource = RCC_PLLSOURCE_HSE;
  RCC_OscInitStruct.PLL.PLLM = 4;
  RCC_OscInitStruct.PLL.PLLN = 180;
  RCC_OscInitStruct.PLL.PLLP = RCC_PLLP_DIV2;
  RCC_OscInitStruct.PLL.PLLQ = 8;
  RCC_OscInitStruct.PLL.PLLR = 2;
  if (HAL_RCC_OscConfig(&RCC_OscInitStruct) != HAL_OK)
  {
    Error_Handler();
  }

  /** Activate the Over-Drive mode
  */
  if (HAL_PWREx_EnableOverDrive() != HAL_OK)
  {
    Error_Handler();
  }

  /** Initializes the CPU, AHB and APB buses clocks
  */
  RCC_ClkInitStruct.ClockType = RCC_CLOCKTYPE_HCLK|RCC_CLOCKTYPE_SYSCLK
                              |RCC_CLOCKTYPE_PCLK1|RCC_CLOCKTYPE_PCLK2;
  RCC_ClkInitStruct.SYSCLKSource = RCC_SYSCLKSOURCE_PLLCLK;
  RCC_ClkInitStruct.AHBCLKDivider = RCC_SYSCLK_DIV1;
  RCC_ClkInitStruct.APB1CLKDivider = RCC_HCLK_DIV4;
  RCC_ClkInitStruct.APB2CLKDivider = RCC_HCLK_DIV2;

  if (HAL_RCC_ClockConfig(&RCC_ClkInitStruct, FLASH_LATENCY_5) != HAL_OK)
  {
    Error_Handler();
  }
}

static void MX_ADC1_Init(void)
{

  ADC_ChannelConfTypeDef sConfig = {0};

  /** Configure the global features of the ADC (Clock, Resolution, Data Alignment and number of conversion)
  */
  hadc1.Instance = ADC1;
  hadc1.Init.ClockPrescaler = ADC_CLOCK_SYNC_PCLK_DIV4;
  hadc1.Init.Resolution = ADC_RESOLUTION_12B;
  hadc1.Init.ScanConvMode = ENABLE;
  hadc1.Init.ContinuousConvMode = DISABLE;
  hadc1.Init.DiscontinuousConvMode = DISABLE;
  hadc1.Init.ExternalTrigConvEdge = ADC_EXTERNALTRIGCONVEDGE_RISING;
  hadc1.Init.ExternalTrigConv = ADC_EXTERNALTRIGCONV_T2_TRGO;
  hadc1.Init.DataAlign = ADC_DATAALIGN_RIGHT;
  hadc1.Init.NbrOfConversion = 3;
  hadc1.Init.DMAContinuousRequests = ENABLE;
  hadc1.Init.EOCSelection = ADC_EOC_SINGLE_CONV;
  if (HAL_ADC_Init(&hadc1) != HAL_OK)
  {
    Error_Handler();
  }

  /** Configure for the selected ADC regular channel its corresponding rank in the sequencer and its sample time.
  */
  sConfig.Channel = ADC_CHANNEL_9;
  sConfig.Rank = 1;
  sConfig.SamplingTime = ADC_SAMPLETIME_15CYCLES;
  if (HAL_ADC_ConfigChannel(&hadc1, &sConfig) != HAL_OK)
  {
    Error_Handler();
  }

  /** Configure for the selected ADC regular channel its corresponding rank in the sequencer and its sample time.
  */
  sConfig.Channel = ADC_CHANNEL_TEMPSENSOR;
  sConfig.Rank = 2;
  sConfig.SamplingTime = ADC_SAMPLETIME_480CYCLES;
  if (HAL_ADC_ConfigChannel(&hadc1, &sConfig) != HAL_OK)
  {
    Error_Handler();
  }

  /** Configure for the selected ADC regular channel its corresponding rank in the sequencer and its sample time.
  */
  sConfig.Channel = ADC_CHANNEL_VREFINT;
  sConfig.Rank = 3;
  if (HAL_ADC_ConfigChannel(&hadc1, &sConfig) != HAL_OK)
  {
    Error_Handler();
  }

}

static void MX_ADC2_Init(void)
{

  ADC_ChannelConfTypeDef sConfig = {0};

  /** Configure the global features of the ADC (Clock, Resolution, Data Alignment and number of conversion)
  */
  hadc2.Instance = ADC2;
  hadc2.Init.ClockPrescaler = ADC_CLOCK_SYNC_PCLK_DIV4;
  hadc2.Init.Resolution = ADC_RESOLUTION_12B;
  hadc2.Init.ScanConvMode = ENABLE;
  hadc2.Init.ContinuousConvMode = DISABLE;
  hadc2.Init.DiscontinuousConvMode = DISABLE;
  hadc2.Init.ExternalTrigConvEdge = ADC_EXTERNALTRIGCONVEDGE_RISING;
  hadc2.Init.ExternalTrigConv = ADC_EXTERNALTRIGCONV_T3_TRGO;
  hadc2.Init.DataAlign = ADC_DATAALIGN_RIGHT;
  hadc2.Init.NbrOfConversion = 2;
  hadc2.Init.DMAContinuousRequests = ENABLE;
  hadc2.Init.EOCSelection = ADC_EOC_SINGLE_CONV;
  if (HAL_ADC_Init(&hadc2) != HAL_OK)
  {
    Error_Handler();
  }

  /** Configure for the selected ADC regular channel its corresponding rank in the sequencer and its sample time.
  */
  sConfig.Channel = ADC_CHANNEL_12;
  sConfig.Rank = 1;
  sConfig.SamplingTime = ADC_SAMPLETIME_15CYCLES;
  if (HAL_ADC_ConfigChannel(&hadc2, &sConfig) != HAL_OK)
  {
    Error_Handler();
  }

  /** Configure for the selected ADC regular channel its corresponding rank in the sequencer and its sample time.
  */
  sConfig.Channel = ADC_CHANNEL_13;
  sConfig.Rank = 2;
  if (HAL_ADC_ConfigChannel(&hadc2, &sConfig) != HAL_OK)
  {
    Error_Handler();
  }

}

static void MX_CAN2_Init(void)
{

  hcan2.Instance = CAN2;
  hcan2.Init.Prescaler = 5;
  hcan2.Init.Mode = CAN_MODE_NORMAL;
  hcan2.Init.SyncJumpWidth = CAN_SJW_1TQ;
  hcan2.Init.TimeSeg1 = CAN_BS1_15TQ;
  hcan2.Init.TimeSeg2 = CAN_BS2_2TQ;
  hcan2.Init.TimeTriggeredMode = DISABLE;
  hcan2.Init.AutoBusOff = DISABLE;
  hcan2.Init.AutoWakeUp = DISABLE;
  hcan2.Init.AutoRetransmission = DISABLE;
  hcan2.Init.ReceiveFifoLocked = DISABLE;
  hcan2.Init.TransmitFifoPriority = DISABLE;
  if (HAL_CAN_Init(&hcan2) != HAL_OK)
  {
    Error_Handler();
  }
  /* USER CODE BEGIN CAN2_Init 2 */
	/* Filter configured at application level inside vd_CAN_Task_Init() */
  /* USER CODE END CAN2_Init 2 */

}

static void MX_SDIO_SD_Init(void)
{

  hsd.Instance = SDIO;
  hsd.Init.ClockEdge = SDIO_CLOCK_EDGE_RISING;
  hsd.Init.ClockBypass = SDIO_CLOCK_BYPASS_DISABLE;
  hsd.Init.ClockPowerSave = SDIO_CLOCK_POWER_SAVE_DISABLE;
  hsd.Init.BusWide = SDIO_BUS_WIDE_1B;
  hsd.Init.HardwareFlowControl = SDIO_HARDWARE_FLOW_CONTROL_DISABLE;
  hsd.Init.ClockDiv = 4;

}

static void MX_TIM2_Init(void)
{

  TIM_ClockConfigTypeDef sClockSourceConfig = {0};
  TIM_MasterConfigTypeDef sMasterConfig = {0};

  htim2.Instance = TIM2;
  htim2.Init.Prescaler = 90-1;
  htim2.Init.CounterMode = TIM_COUNTERMODE_UP;
  htim2.Init.Period = 25000-1;
  htim2.Init.ClockDivision = TIM_CLOCKDIVISION_DIV1;
  htim2.Init.AutoReloadPreload = TIM_AUTORELOAD_PRELOAD_DISABLE;
  if (HAL_TIM_Base_Init(&htim2) != HAL_OK)
  {
    Error_Handler();
  }
  sClockSourceConfig.ClockSource = TIM_CLOCKSOURCE_INTERNAL;
  if (HAL_TIM_ConfigClockSource(&htim2, &sClockSourceConfig) != HAL_OK)
  {
    Error_Handler();
  }
  sMasterConfig.MasterOutputTrigger = TIM_TRGO_UPDATE;
  sMasterConfig.MasterSlaveMode = TIM_MASTERSLAVEMODE_DISABLE;
  if (HAL_TIMEx_MasterConfigSynchronization(&htim2, &sMasterConfig) != HAL_OK)
  {
    Error_Handler();
  }

}

static void MX_TIM3_Init(void)
{

  TIM_ClockConfigTypeDef sClockSourceConfig = {0};
  TIM_MasterConfigTypeDef sMasterConfig = {0};

  htim3.Instance = TIM3;
  htim3.Init.Prescaler = 90-1;
  htim3.Init.CounterMode = TIM_COUNTERMODE_UP;
  htim3.Init.Period = 200-1;
  htim3.Init.ClockDivision = TIM_CLOCKDIVISION_DIV1;
  htim3.Init.AutoReloadPreload = TIM_AUTORELOAD_PRELOAD_DISABLE;
  if (HAL_TIM_Base_Init(&htim3) != HAL_OK)
  {
    Error_Handler();
  }
  sClockSourceConfig.ClockSource = TIM_CLOCKSOURCE_INTERNAL;
  if (HAL_TIM_ConfigClockSource(&htim3, &sClockSourceConfig) != HAL_OK)
  {
    Error_Handler();
  }
  sMasterConfig.MasterOutputTrigger = TIM_TRGO_UPDATE;
  sMasterConfig.MasterSlaveMode = TIM_MASTERSLAVEMODE_DISABLE;
  if (HAL_TIMEx_MasterConfigSynchronization(&htim3, &sMasterConfig) != HAL_OK)
  {
    Error_Handler();
  }

}

static void MX_USART3_UART_Init(void)
{

  huart3.Instance = USART3;
  huart3.Init.BaudRate = 115200;
  huart3.Init.WordLength = UART_WORDLENGTH_8B;
  huart3.Init.StopBits = UART_STOPBITS_1;
  huart3.Init.Parity = UART_PARITY_NONE;
  huart3.Init.Mode = UART_MODE_TX_RX;
  huart3.Init.HwFlowCtl = UART_HWCONTROL_NONE;
  huart3.Init.OverSampling = UART_OVERSAMPLING_16;
  if (HAL_UART_Init(&huart3) != HAL_OK)
  {
    Error_Handler();
  }

}

static void MX_USART6_UART_Init(void)
{

  huart6.Instance = USART6;
  huart6.Init.BaudRate = 115200;
  huart6.Init.WordLength = UART_WORDLENGTH_8B;
  huart6.Init.StopBits = UART_STOPBITS_1;
  huart6.Init.Parity = UART_PARITY_NONE;
  huart6.Init.Mode = UART_MODE_TX_RX;
  huart6.Init.HwFlowCtl = UART_HWCONTROL_NONE;
  huart6.Init.OverSampling = UART_OVERSAMPLING_16;
  if (HAL_UART_Init(&huart6) != HAL_OK)
  {
    Error_Handler();
  }

}

static void MX_SPI2_Init(void)
{
  hspi2.Instance = SPI2;
  hspi2.Init.Mode = SPI_MODE_MASTER;
  hspi2.Init.Direction = SPI_DIRECTION_2LINES;
  hspi2.Init.DataSize = SPI_DATASIZE_8BIT;
  hspi2.Init.CLKPolarity = SPI_POLARITY_HIGH;
  hspi2.Init.CLKPhase = SPI_PHASE_2EDGE;
  hspi2.Init.NSS = SPI_NSS_SOFT;
  hspi2.Init.BaudRatePrescaler = SPI_BAUDRATEPRESCALER_64;
  hspi2.Init.FirstBit = SPI_FIRSTBIT_MSB;
  hspi2.Init.TIMode = SPI_TIMODE_DISABLE;
  hspi2.Init.CRCCalculation = SPI_CRCCALCULATION_DISABLE;
  hspi2.Init.CRCPolynomial = 10;
  if (HAL_SPI_Init(&hspi2) != HAL_OK)
  {
    Error_Handler();
  }
}

static void MX_DMA_Init(void)
{

  /* DMA controller clock enable */
  __HAL_RCC_DMA2_CLK_ENABLE();

  /* DMA interrupt init */
  /* DMA2_Stream0_IRQn interrupt configuration */
  HAL_NVIC_SetPriority(DMA2_Stream0_IRQn, 5, 0);
  HAL_NVIC_EnableIRQ(DMA2_Stream0_IRQn);
  /* DMA2_Stream1_IRQn interrupt configuration */
  HAL_NVIC_SetPriority(DMA2_Stream1_IRQn, 5, 0);
  HAL_NVIC_EnableIRQ(DMA2_Stream1_IRQn);
  /* DMA2_Stream2_IRQn interrupt configuration */
  HAL_NVIC_SetPriority(DMA2_Stream2_IRQn, 5, 0);
  HAL_NVIC_EnableIRQ(DMA2_Stream2_IRQn);

}

static void MX_GPIO_Init(void)
{
  GPIO_InitTypeDef GPIO_InitStruct = {0};

  /* GPIO Ports Clock Enable */
  __HAL_RCC_GPIOE_CLK_ENABLE();
  __HAL_RCC_GPIOB_CLK_ENABLE();
  __HAL_RCC_GPIOC_CLK_ENABLE();
  __HAL_RCC_GPIOA_CLK_ENABLE();
  __HAL_RCC_GPIOG_CLK_ENABLE();
  __HAL_RCC_GPIOD_CLK_ENABLE();
  __HAL_RCC_GPIOI_CLK_ENABLE();
  __HAL_RCC_GPIOF_CLK_ENABLE();
  __HAL_RCC_GPIOK_CLK_ENABLE();
  __HAL_RCC_GPIOH_CLK_ENABLE();
  __HAL_RCC_GPIOJ_CLK_ENABLE();

  /*Configure GPIO pin Output Level */
  HAL_GPIO_WritePin(GPIOE, SPKR_HP_Pin|AUDIO_RST_Pin, GPIO_PIN_RESET);

  /*Configure GPIO pin Output Level */
  HAL_GPIO_WritePin(GPIOD, LED3_Pin|LED2_Pin, GPIO_PIN_RESET);

  /*Configure GPIO pin Output Level */
  HAL_GPIO_WritePin(LED4_GPIO_Port, LED4_Pin, GPIO_PIN_RESET);

  /*Configure GPIO pin Output Level */
  HAL_GPIO_WritePin(LED1_GPIO_Port, LED1_Pin, GPIO_PIN_RESET);

  /*Configure GPIO pin Output Level — BMS SPI2 chip-select, idle HIGH
   * (LTC6813 CS is active-low; must be deselected before MX_SPI2_Init()
   * or any BMS driver call, hence set here in MX_GPIO_Init()). */
  HAL_GPIO_WritePin(BMS_SPI_CS_GPIO_Port, BMS_SPI_CS_Pin, GPIO_PIN_SET);

  /*Configure GPIO pin Output Level */
  HAL_GPIO_WritePin(GPIOB, OTG_FS1_PowerSwitchOn_Pin|EXT_RESET_Pin, GPIO_PIN_RESET);

  /*Configure GPIO pin Output Level */
  HAL_GPIO_WritePin(LCD_BL_CTRL_GPIO_Port, LCD_BL_CTRL_Pin, GPIO_PIN_RESET);

  /*Configure GPIO pins : SAI1_FSA_Pin SAI1_SCKA_Pin */
  GPIO_InitStruct.Pin = SAI1_FSA_Pin|SAI1_SCKA_Pin;
  GPIO_InitStruct.Mode = GPIO_MODE_AF_PP;
  GPIO_InitStruct.Pull = GPIO_NOPULL;
  GPIO_InitStruct.Speed = GPIO_SPEED_FREQ_LOW;
  GPIO_InitStruct.Alternate = GPIO_AF6_SAI1;
  HAL_GPIO_Init(GPIOE, &GPIO_InitStruct);

  /*Configure GPIO pins : SPKR_HP_Pin AUDIO_RST_Pin */
  GPIO_InitStruct.Pin = SPKR_HP_Pin|AUDIO_RST_Pin;
  GPIO_InitStruct.Mode = GPIO_MODE_OUTPUT_PP;
  GPIO_InitStruct.Pull = GPIO_NOPULL;
  GPIO_InitStruct.Speed = GPIO_SPEED_FREQ_LOW;
  HAL_GPIO_Init(GPIOE, &GPIO_InitStruct);

  /*Configure GPIO pins : FMC_NBL1_Pin FMC_NBL0_Pin D5_Pin D6_Pin
                           D8_Pin D11_Pin D4_Pin D7_Pin
                           D9_Pin D12_Pin D10_Pin */
  GPIO_InitStruct.Pin = FMC_NBL1_Pin|FMC_NBL0_Pin|D5_Pin|D6_Pin
                          |D8_Pin|D11_Pin|D4_Pin|D7_Pin
                          |D9_Pin|D12_Pin|D10_Pin;
  GPIO_InitStruct.Mode = GPIO_MODE_AF_PP;
  GPIO_InitStruct.Pull = GPIO_NOPULL;
  GPIO_InitStruct.Speed = GPIO_SPEED_FREQ_VERY_HIGH;
  GPIO_InitStruct.Alternate = GPIO_AF12_FMC;
  HAL_GPIO_Init(GPIOE, &GPIO_InitStruct);

  /*Configure GPIO pins : I2C1_SCL_Pin I2C1_SDA_Pin */
  GPIO_InitStruct.Pin = I2C1_SCL_Pin|I2C1_SDA_Pin;
  GPIO_InitStruct.Mode = GPIO_MODE_AF_OD;
  GPIO_InitStruct.Pull = GPIO_NOPULL;
  GPIO_InitStruct.Speed = GPIO_SPEED_FREQ_VERY_HIGH;
  GPIO_InitStruct.Alternate = GPIO_AF4_I2C1;
  HAL_GPIO_Init(GPIOB, &GPIO_InitStruct);

  /*Configure GPIO pin : I2S3_CK_Pin */
  GPIO_InitStruct.Pin = I2S3_CK_Pin;
  GPIO_InitStruct.Mode = GPIO_MODE_AF_PP;
  GPIO_InitStruct.Pull = GPIO_NOPULL;
  GPIO_InitStruct.Speed = GPIO_SPEED_FREQ_LOW;
  GPIO_InitStruct.Alternate = GPIO_AF6_SPI3;
  HAL_GPIO_Init(I2S3_CK_GPIO_Port, &GPIO_InitStruct);

  /*Configure GPIO pin : OTG_FS1_OverCurrent_Pin */
  GPIO_InitStruct.Pin = OTG_FS1_OverCurrent_Pin;
  GPIO_InitStruct.Mode = GPIO_MODE_IT_RISING;
  GPIO_InitStruct.Pull = GPIO_NOPULL;
  HAL_GPIO_Init(OTG_FS1_OverCurrent_GPIO_Port, &GPIO_InitStruct);

  /*Configure GPIO pin : QSPI_BK1_NCS_Pin */
  GPIO_InitStruct.Pin = QSPI_BK1_NCS_Pin;
  GPIO_InitStruct.Mode = GPIO_MODE_AF_PP;
  GPIO_InitStruct.Pull = GPIO_NOPULL;
  GPIO_InitStruct.Speed = GPIO_SPEED_FREQ_VERY_HIGH;
  GPIO_InitStruct.Alternate = GPIO_AF10_QSPI;
  HAL_GPIO_Init(QSPI_BK1_NCS_GPIO_Port, &GPIO_InitStruct);

  /*Configure GPIO pins : SDNCAS_Pin SDCLK_Pin A11_Pin A10_Pin
                           PG5 PG4 */
  GPIO_InitStruct.Pin = SDNCAS_Pin|SDCLK_Pin|A11_Pin|A10_Pin
                          |GPIO_PIN_5|GPIO_PIN_4;
  GPIO_InitStruct.Mode = GPIO_MODE_AF_PP;
  GPIO_InitStruct.Pull = GPIO_NOPULL;
  GPIO_InitStruct.Speed = GPIO_SPEED_FREQ_VERY_HIGH;
  GPIO_InitStruct.Alternate = GPIO_AF12_FMC;
  HAL_GPIO_Init(GPIOG, &GPIO_InitStruct);

  /*Configure GPIO pin : MIC_DATA_Pin */
  GPIO_InitStruct.Pin = MIC_DATA_Pin;
  GPIO_InitStruct.Mode = GPIO_MODE_AF_PP;
  GPIO_InitStruct.Pull = GPIO_NOPULL;
  GPIO_InitStruct.Speed = GPIO_SPEED_FREQ_LOW;
  GPIO_InitStruct.Alternate = GPIO_AF6_SAI1;
  HAL_GPIO_Init(MIC_DATA_GPIO_Port, &GPIO_InitStruct);

  /*Configure GPIO pins : D2_Pin D3_Pin D1_Pin D15_Pin
                           D0_Pin D14_Pin D13_Pin */
  GPIO_InitStruct.Pin = D2_Pin|D3_Pin|D1_Pin|D15_Pin
                          |D0_Pin|D14_Pin|D13_Pin;
  GPIO_InitStruct.Mode = GPIO_MODE_AF_PP;
  GPIO_InitStruct.Pull = GPIO_NOPULL;
  GPIO_InitStruct.Speed = GPIO_SPEED_FREQ_VERY_HIGH;
  GPIO_InitStruct.Alternate = GPIO_AF12_FMC;
  HAL_GPIO_Init(GPIOD, &GPIO_InitStruct);

  /*Configure GPIO pins : USB_FS1_P_Pin USB_FS1_N_Pin USB_FS1_ID_Pin */
  GPIO_InitStruct.Pin = USB_FS1_P_Pin|USB_FS1_N_Pin|USB_FS1_ID_Pin;
  GPIO_InitStruct.Mode = GPIO_MODE_AF_PP;
  GPIO_InitStruct.Pull = GPIO_NOPULL;
  GPIO_InitStruct.Speed = GPIO_SPEED_FREQ_VERY_HIGH;
  GPIO_InitStruct.Alternate = GPIO_AF10_OTG_FS;
  HAL_GPIO_Init(GPIOA, &GPIO_InitStruct);

  /*Configure GPIO pins : FMC_NBL2_Pin D27_Pin D26_Pin FMC_NBL3_Pin
                           D29_Pin D31_Pin D28_Pin D25_Pin
                           D30_Pin D24_Pin */
  GPIO_InitStruct.Pin = FMC_NBL2_Pin|D27_Pin|D26_Pin|FMC_NBL3_Pin
                          |D29_Pin|D31_Pin|D28_Pin|D25_Pin
                          |D30_Pin|D24_Pin;
  GPIO_InitStruct.Mode = GPIO_MODE_AF_PP;
  GPIO_InitStruct.Pull = GPIO_NOPULL;
  GPIO_InitStruct.Speed = GPIO_SPEED_FREQ_VERY_HIGH;
  GPIO_InitStruct.Alternate = GPIO_AF12_FMC;
  HAL_GPIO_Init(GPIOI, &GPIO_InitStruct);

  /*Configure GPIO pins : LED3_Pin LED2_Pin */
  GPIO_InitStruct.Pin = LED3_Pin|LED2_Pin;
  GPIO_InitStruct.Mode = GPIO_MODE_OUTPUT_PP;
  GPIO_InitStruct.Pull = GPIO_NOPULL;
  GPIO_InitStruct.Speed = GPIO_SPEED_FREQ_LOW;
  HAL_GPIO_Init(GPIOD, &GPIO_InitStruct);

  /*Configure GPIO pins : A0_Pin A1_Pin A2_Pin A3_Pin
                           A4_Pin A5_Pin A6_Pin A9_Pin
                           A7_Pin A8_Pin SDNMT48LC4M32B2B5_6A_RAS_RAS___Pin */
  GPIO_InitStruct.Pin = A0_Pin|A1_Pin|A2_Pin|A3_Pin
                          |A4_Pin|A5_Pin|A6_Pin|A9_Pin
                          |A7_Pin|A8_Pin|SDNMT48LC4M32B2B5_6A_RAS_RAS___Pin;
  GPIO_InitStruct.Mode = GPIO_MODE_AF_PP;
  GPIO_InitStruct.Pull = GPIO_NOPULL;
  GPIO_InitStruct.Speed = GPIO_SPEED_FREQ_VERY_HIGH;
  GPIO_InitStruct.Alternate = GPIO_AF12_FMC;
  HAL_GPIO_Init(GPIOF, &GPIO_InitStruct);

  /*Configure GPIO pin : LED4_Pin */
  GPIO_InitStruct.Pin = LED4_Pin;
  GPIO_InitStruct.Mode = GPIO_MODE_OUTPUT_PP;
  GPIO_InitStruct.Pull = GPIO_NOPULL;
  GPIO_InitStruct.Speed = GPIO_SPEED_FREQ_LOW;
  HAL_GPIO_Init(LED4_GPIO_Port, &GPIO_InitStruct);

  /*Configure GPIO pin : BMS_SPI_CS_Pin (PH6) — LTC6813 chip-select, plain
   * GPIO output, software-driven (SPI2 NSS=SOFT). See
   * Drivers_Custom/AMS_bms_driver.h for the full wiring note. */
  GPIO_InitStruct.Pin = BMS_SPI_CS_Pin;
  GPIO_InitStruct.Mode = GPIO_MODE_OUTPUT_PP;
  GPIO_InitStruct.Pull = GPIO_NOPULL;
  GPIO_InitStruct.Speed = GPIO_SPEED_FREQ_LOW;
  HAL_GPIO_Init(BMS_SPI_CS_GPIO_Port, &GPIO_InitStruct);

  /*Configure GPIO pins : D23_Pin D21_Pin D22_Pin SDNE0_Pin
                           SDCKE0_Pin D20_Pin D17_Pin D19_Pin
                           D16_Pin D18_Pin */
  GPIO_InitStruct.Pin = D23_Pin|D21_Pin|D22_Pin|SDNE0_Pin
                          |SDCKE0_Pin|D20_Pin|D17_Pin|D19_Pin
                          |D16_Pin|D18_Pin;
  GPIO_InitStruct.Mode = GPIO_MODE_AF_PP;
  GPIO_InitStruct.Pull = GPIO_NOPULL;
  GPIO_InitStruct.Speed = GPIO_SPEED_FREQ_VERY_HIGH;
  GPIO_InitStruct.Alternate = GPIO_AF12_FMC;
  HAL_GPIO_Init(GPIOH, &GPIO_InitStruct);

  /*Configure GPIO pin : VBUS_FS1_Pin */
  GPIO_InitStruct.Pin = VBUS_FS1_Pin;
  GPIO_InitStruct.Mode = GPIO_MODE_AF_PP;
  GPIO_InitStruct.Pull = GPIO_NOPULL;
  HAL_GPIO_Init(VBUS_FS1_GPIO_Port, &GPIO_InitStruct);

  /*Configure GPIO pins : I2C2_SCL_Pin I2C2_SDA_Pin */
  GPIO_InitStruct.Pin = I2C2_SCL_Pin|I2C2_SDA_Pin;
  GPIO_InitStruct.Mode = GPIO_MODE_AF_OD;
  GPIO_InitStruct.Pull = GPIO_NOPULL;
  GPIO_InitStruct.Speed = GPIO_SPEED_FREQ_VERY_HIGH;
  GPIO_InitStruct.Alternate = GPIO_AF4_I2C2;
  HAL_GPIO_Init(GPIOH, &GPIO_InitStruct);

  /*Configure GPIO pin : SAI1_MCLKA_Pin */
  GPIO_InitStruct.Pin = SAI1_MCLKA_Pin;
  GPIO_InitStruct.Mode = GPIO_MODE_AF_PP;
  GPIO_InitStruct.Pull = GPIO_NOPULL;
  GPIO_InitStruct.Speed = GPIO_SPEED_FREQ_LOW;
  GPIO_InitStruct.Alternate = GPIO_AF6_SAI1;
  HAL_GPIO_Init(SAI1_MCLKA_GPIO_Port, &GPIO_InitStruct);

  /*Configure GPIO pin : LED1_Pin */
  GPIO_InitStruct.Pin = LED1_Pin;
  GPIO_InitStruct.Mode = GPIO_MODE_OUTPUT_PP;
  GPIO_InitStruct.Pull = GPIO_NOPULL;
  GPIO_InitStruct.Speed = GPIO_SPEED_FREQ_LOW;
  HAL_GPIO_Init(LED1_GPIO_Port, &GPIO_InitStruct);

  /*Configure GPIO pins : QSPI_BK1_IO2_Pin QSPI_BK1_IO3_Pin QSPI_CLK_Pin */
  GPIO_InitStruct.Pin = QSPI_BK1_IO2_Pin|QSPI_BK1_IO3_Pin|QSPI_CLK_Pin;
  GPIO_InitStruct.Mode = GPIO_MODE_AF_PP;
  GPIO_InitStruct.Pull = GPIO_NOPULL;
  GPIO_InitStruct.Speed = GPIO_SPEED_FREQ_VERY_HIGH;
  GPIO_InitStruct.Alternate = GPIO_AF9_QSPI;
  HAL_GPIO_Init(GPIOF, &GPIO_InitStruct);

  /*Configure GPIO pins : QSPI_BK1_IO1_Pin QSPI_BK1_IO0_Pin */
  GPIO_InitStruct.Pin = QSPI_BK1_IO1_Pin|QSPI_BK1_IO0_Pin;
  GPIO_InitStruct.Mode = GPIO_MODE_AF_PP;
  GPIO_InitStruct.Pull = GPIO_NOPULL;
  GPIO_InitStruct.Speed = GPIO_SPEED_FREQ_VERY_HIGH;
  GPIO_InitStruct.Alternate = GPIO_AF10_QSPI;
  HAL_GPIO_Init(GPIOF, &GPIO_InitStruct);

  /*Configure GPIO pin : SDNWE_Pin */
  GPIO_InitStruct.Pin = SDNWE_Pin;
  GPIO_InitStruct.Mode = GPIO_MODE_AF_PP;
  GPIO_InitStruct.Pull = GPIO_NOPULL;
  GPIO_InitStruct.Speed = GPIO_SPEED_FREQ_VERY_HIGH;
  GPIO_InitStruct.Alternate = GPIO_AF12_FMC;
  HAL_GPIO_Init(SDNWE_GPIO_Port, &GPIO_InitStruct);

  /*Configure GPIO pins : OTG_FS1_PowerSwitchOn_Pin EXT_RESET_Pin */
  GPIO_InitStruct.Pin = OTG_FS1_PowerSwitchOn_Pin|EXT_RESET_Pin;
  GPIO_InitStruct.Mode = GPIO_MODE_OUTPUT_PP;
  GPIO_InitStruct.Pull = GPIO_NOPULL;
  GPIO_InitStruct.Speed = GPIO_SPEED_FREQ_LOW;
  HAL_GPIO_Init(GPIOB, &GPIO_InitStruct);

  /*Configure GPIO pin : MIC_CK_Pin */
  GPIO_InitStruct.Pin = MIC_CK_Pin;
  GPIO_InitStruct.Mode = GPIO_MODE_AF_PP;
  GPIO_InitStruct.Pull = GPIO_NOPULL;
  GPIO_InitStruct.Speed = GPIO_SPEED_FREQ_LOW;
  GPIO_InitStruct.Alternate = GPIO_AF2_TIM4;
  HAL_GPIO_Init(MIC_CK_GPIO_Port, &GPIO_InitStruct);

  /*Configure GPIO pin : uSD_Detect_Pin */
  GPIO_InitStruct.Pin = uSD_Detect_Pin;
  GPIO_InitStruct.Mode = GPIO_MODE_INPUT;
  GPIO_InitStruct.Pull = GPIO_NOPULL;
  HAL_GPIO_Init(uSD_Detect_GPIO_Port, &GPIO_InitStruct);

  /*Configure GPIO pin : LCD_INT_Pin */
  GPIO_InitStruct.Pin = LCD_INT_Pin;
  GPIO_InitStruct.Mode = GPIO_MODE_IT_RISING;
  GPIO_InitStruct.Pull = GPIO_NOPULL;
  HAL_GPIO_Init(LCD_INT_GPIO_Port, &GPIO_InitStruct);

  /*Configure GPIO pin : Boton_Azul_Pin */
  GPIO_InitStruct.Pin = Boton_Azul_Pin;
  GPIO_InitStruct.Mode = GPIO_MODE_INPUT;
  GPIO_InitStruct.Pull = GPIO_NOPULL;
  HAL_GPIO_Init(Boton_Azul_GPIO_Port, &GPIO_InitStruct);

  /*Configure GPIO pin : DSI_TE_Pin */
  GPIO_InitStruct.Pin = DSI_TE_Pin;
  GPIO_InitStruct.Mode = GPIO_MODE_AF_PP;
  GPIO_InitStruct.Pull = GPIO_NOPULL;
  GPIO_InitStruct.Speed = GPIO_SPEED_FREQ_LOW;
  GPIO_InitStruct.Alternate = GPIO_AF13_DSI;
  HAL_GPIO_Init(DSI_TE_GPIO_Port, &GPIO_InitStruct);

  /*Configure GPIO pin : LCD_BL_CTRL_Pin */
  GPIO_InitStruct.Pin = LCD_BL_CTRL_Pin;
  GPIO_InitStruct.Mode = GPIO_MODE_OUTPUT_PP;
  GPIO_InitStruct.Pull = GPIO_NOPULL;
  GPIO_InitStruct.Speed = GPIO_SPEED_FREQ_LOW;
  HAL_GPIO_Init(LCD_BL_CTRL_GPIO_Port, &GPIO_InitStruct);

}

/* USER CODE BEGIN 4 */

/* --- UART printf redirect (USB-UART3) --- */
int __io_putchar(char ch) {
	HAL_UART_Transmit(&huart3, (uint8_t*) &ch, 1, HAL_MAX_DELAY);
	return ch;
}

/* -----------------------------------------------------------------------
 * CAN2 RX callback - FIFO0 (triggered by CAN2_RX0 interrupt)
 *
 * NOTE: On STM32F4 CAN1 and CAN2 share the same filter bank pool.
 *       CAN2 is the slave, so CAN1 clock MUST also be enabled even if
 *       only CAN2 is used (done automatically by HAL_CAN_MspInit).
 *       Filter banks 14-27 are assigned to CAN2 (SlaveStartFilterBank=14).
 *
 * FIFO choice: filters are assigned to CAN_RX_FIFO0 -> CAN2_RX0_IRQn fires
 *              -> this callback is invoked. CAN_RX_FIFO1 / CAN2_RX1_IRQn
 *              is not used and stays disabled.
 * ----------------------------------------------------------------------- */
void HAL_CAN_RxFifo0MsgPendingCallback(CAN_HandleTypeDef *hcan) {
	if (hcan->Instance == CAN2) {
		CAN_RxHeaderTypeDef RxHeader;
		uint8_t RxData[8];

		if (HAL_CAN_GetRxMessage(hcan, CAN_RX_FIFO0, &RxHeader, RxData)
				== HAL_OK) {
			/* ISR minima: solo entrega el paquete crudo a la Queue.
			 * El parseo y la actualizacion del Broker lo hace la tarea RTOS. */
			vd_CAN_RxQueue_PostFromISR(&RxHeader, RxData);
		}
	}
}

/* USER CODE END 4 */

void StartDefaultTask(void *argument)
{
  /* USER CODE BEGIN 5 */
	vd_Algorithms_Task_Init();
	vd_Algorithms_Manager_TaskProcess();
  /* USER CODE END 5 */
}

void ADC_Start(void *argument)
{
  /* USER CODE BEGIN ADC_Start */
#if TASK_ADC_ENABLE
	vd_ADC_Task_Init(&hadc1, &hadc2, &htim2, &htim3);
	vd_ADC_Manager_TaskProcess();
#else
	osThreadExit();
#endif
  /* USER CODE END ADC_Start */
}

void SD_Card_Start(void *argument)
{
  /* USER CODE BEGIN SD_Card_Start */
#if (TASK_SD_CARD_ENABLE == 1) || (FEATURE_LOGGER_PRINT_ENABLE == 1)
	vd_Logger_Task_Init();
	vd_Logger_Manager_TaskProcess();
#else
	osThreadExit();
#endif
  /* USER CODE END SD_Card_Start */
}

void CAN_Start(void *argument)
{
  /* USER CODE BEGIN CAN_Start */
#if TASK_CAN_ENABLE
	vd_CAN_Task_Init(&hcan2);
	vd_CAN_Manager_TaskProcess();
#else
	osThreadExit();
#endif
  /* USER CODE END CAN_Start */
}

void Flash_Memory_Start(void *argument)
{
  /* USER CODE BEGIN Flash_Memory_Start */
#if TASK_FLASH_MEMO_ENABLE
	/* vd_Flash_Task_Init() already ran in main() before osKernelStart() */
	vd_Flash_Manager_TaskProcess();
#else
	osThreadExit();
#endif
  /* USER CODE END Flash_Memory_Start */
}

void GPS_Start_Task(void *argument)
{
  /* USER CODE BEGIN GPS_Start_Task */
#if TASK_GPS_ENABLE
	/* huart3 = BENCH TEST wiring only: ST-LINK USB/VCP, NMEA fed from a PC.
	 * On the actual bike this MUST be &huart6 (see README.md's CAN2/UART
	 * peripheral map) — huart3 is also the debug printf console and has no
	 * DMA stream wired, so the driver falls back to interrupt-mode
	 * reception for it automatically (see AMS_gps_driver.c). Swap this to
	 * &huart6 before flashing onto the vehicle. */
	vd_GPS_Task_Init(&huart3);
	vd_GPS_Manager_TaskProcess();
#else
	osThreadExit();
#endif
  /* USER CODE END GPS_Start_Task */
}

void BMS_Start(void *argument)
{
  /* USER CODE BEGIN BMS_Start */
#if TASK_BMS_ENABLE
	vd_BMS_Task_Init(&hspi2);
	vd_BMS_Manager_TaskProcess();
#else
	osThreadExit();
#endif
  /* USER CODE END BMS_Start */
}

void Error_Handler(void)
{
	__disable_irq();
	while (1) {
	}
}

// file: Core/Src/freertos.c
/* USER CODE BEGIN Header */
/**
  ******************************************************************************
  * File Name          : freertos.c
  * Description        : Code for freertos applications
  ******************************************************************************
  * @attention
  *
  * Copyright (c) 2026 STMicroelectronics.
  * All rights reserved.
  *
  * This software is licensed under terms that can be found in the LICENSE file
  * in the root directory of this software component.
  * If no LICENSE file comes with this software, it is provided AS-IS.
  *
  ******************************************************************************
  */
/* USER CODE END Header */

#include "FreeRTOS.h"
#include "task.h"
#include "main.h"

/* USER CODE BEGIN Application */

/**
 * @brief FreeRTOS stack-overflow hook (configCHECK_FOR_STACK_OVERFLOW in
 *        FreeRTOSConfig.h). Overrides the __WEAK no-op default in cmsis_os2.c.
 *
 *        Deliberately does the bare minimum: the stack that just overflowed
 *        may have trashed adjacent RAM, so this does NOT go through the LED
 *        driver, the Broker, or printf (all of which use more stack and
 *        state than we can trust right now) — just a direct register write
 *        to light the red LED, then halt with interrupts off so a debugger
 *        or watchdog reset can take over instead of the corruption
 *        propagating further.
 */
void vApplicationStackOverflowHook(TaskHandle_t xTask, signed char *pcTaskName)
{
    (void)xTask;
    (void)pcTaskName;

    HAL_GPIO_WritePin(LED3_GPIO_Port, LED3_Pin, GPIO_PIN_RESET); /* RED, active-low: RESET = ON */

    __disable_irq();
    for (;;) {
        /* Halt here — do not attempt to recover or keep scheduling. */
    }
}

/* USER CODE END Application */
